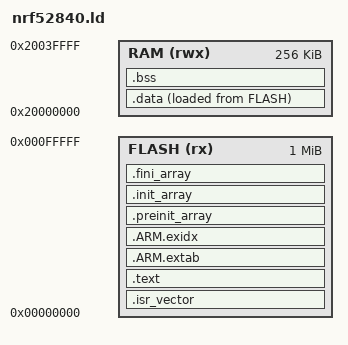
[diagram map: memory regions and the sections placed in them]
ENTRY(Reset_Handler)

MEMORY
{
  FLASH (rx)  : ORIGIN = 0x00000000, LENGTH = 1024K
  RAM   (rwx) : ORIGIN = 0x20000000, LENGTH = 256K
}

__StackTop = ORIGIN(RAM) + LENGTH(RAM);
__StackLimit = __StackTop - 0x1000;
PROVIDE(_estack = __StackTop);

SECTIONS
{
  .isr_vector :
  {
    . = ALIGN(4);
    KEEP(*(.isr_vector))
    . = ALIGN(4);
  } > FLASH

  .text :
  {
    . = ALIGN(4);
    *(.text*)
    *(.rodata*)
    *(.glue_7)
    *(.glue_7t)
    . = ALIGN(4);
  } > FLASH

  .ARM.extab :
  {
    *(.ARM.extab* .gnu.linkonce.armextab.*)
  } > FLASH

  .ARM.exidx :
  {
    __exidx_start = .;
    *(.ARM.exidx* .gnu.linkonce.armexidx.*)
    __exidx_end = .;
  } > FLASH

  .preinit_array :
  {
    PROVIDE_HIDDEN(__preinit_array_start = .);
    KEEP(*(.preinit_array*))
    PROVIDE_HIDDEN(__preinit_array_end = .);
  } > FLASH

  .init_array :
  {
    PROVIDE_HIDDEN(__init_array_start = .);
    KEEP(*(SORT_BY_INIT_PRIORITY(.init_array.*)))
    KEEP(*(.init_array*))
    PROVIDE_HIDDEN(__init_array_end = .);
  } > FLASH

  .fini_array :
  {
    PROVIDE_HIDDEN(__fini_array_start = .);
    KEEP(*(SORT_BY_INIT_PRIORITY(.fini_array.*)))
    KEEP(*(.fini_array*))
    PROVIDE_HIDDEN(__fini_array_end = .);
  } > FLASH

  _sidata = LOADADDR(.data);
  .data :
  {
    . = ALIGN(4);
    _sdata = .;
    *(.data*)
    . = ALIGN(4);
    _edata = .;
  } > RAM AT > FLASH

  .bss (NOLOAD) :
  {
    . = ALIGN(4);
    _sbss = .;
    *(.bss*)
    *(COMMON)
    . = ALIGN(4);
    _ebss = .;
  } > RAM

  . = ALIGN(8);
  __HeapBase = .;
  PROVIDE(end = .);
  PROVIDE(_end = .);
  __HeapLimit = __StackLimit;

  /DISCARD/ :
  {
    *(.comment)
    *(.note*)
  }
}

ASSERT(__StackLimit >= __HeapBase, "RAM overflowed by reserved stack")
